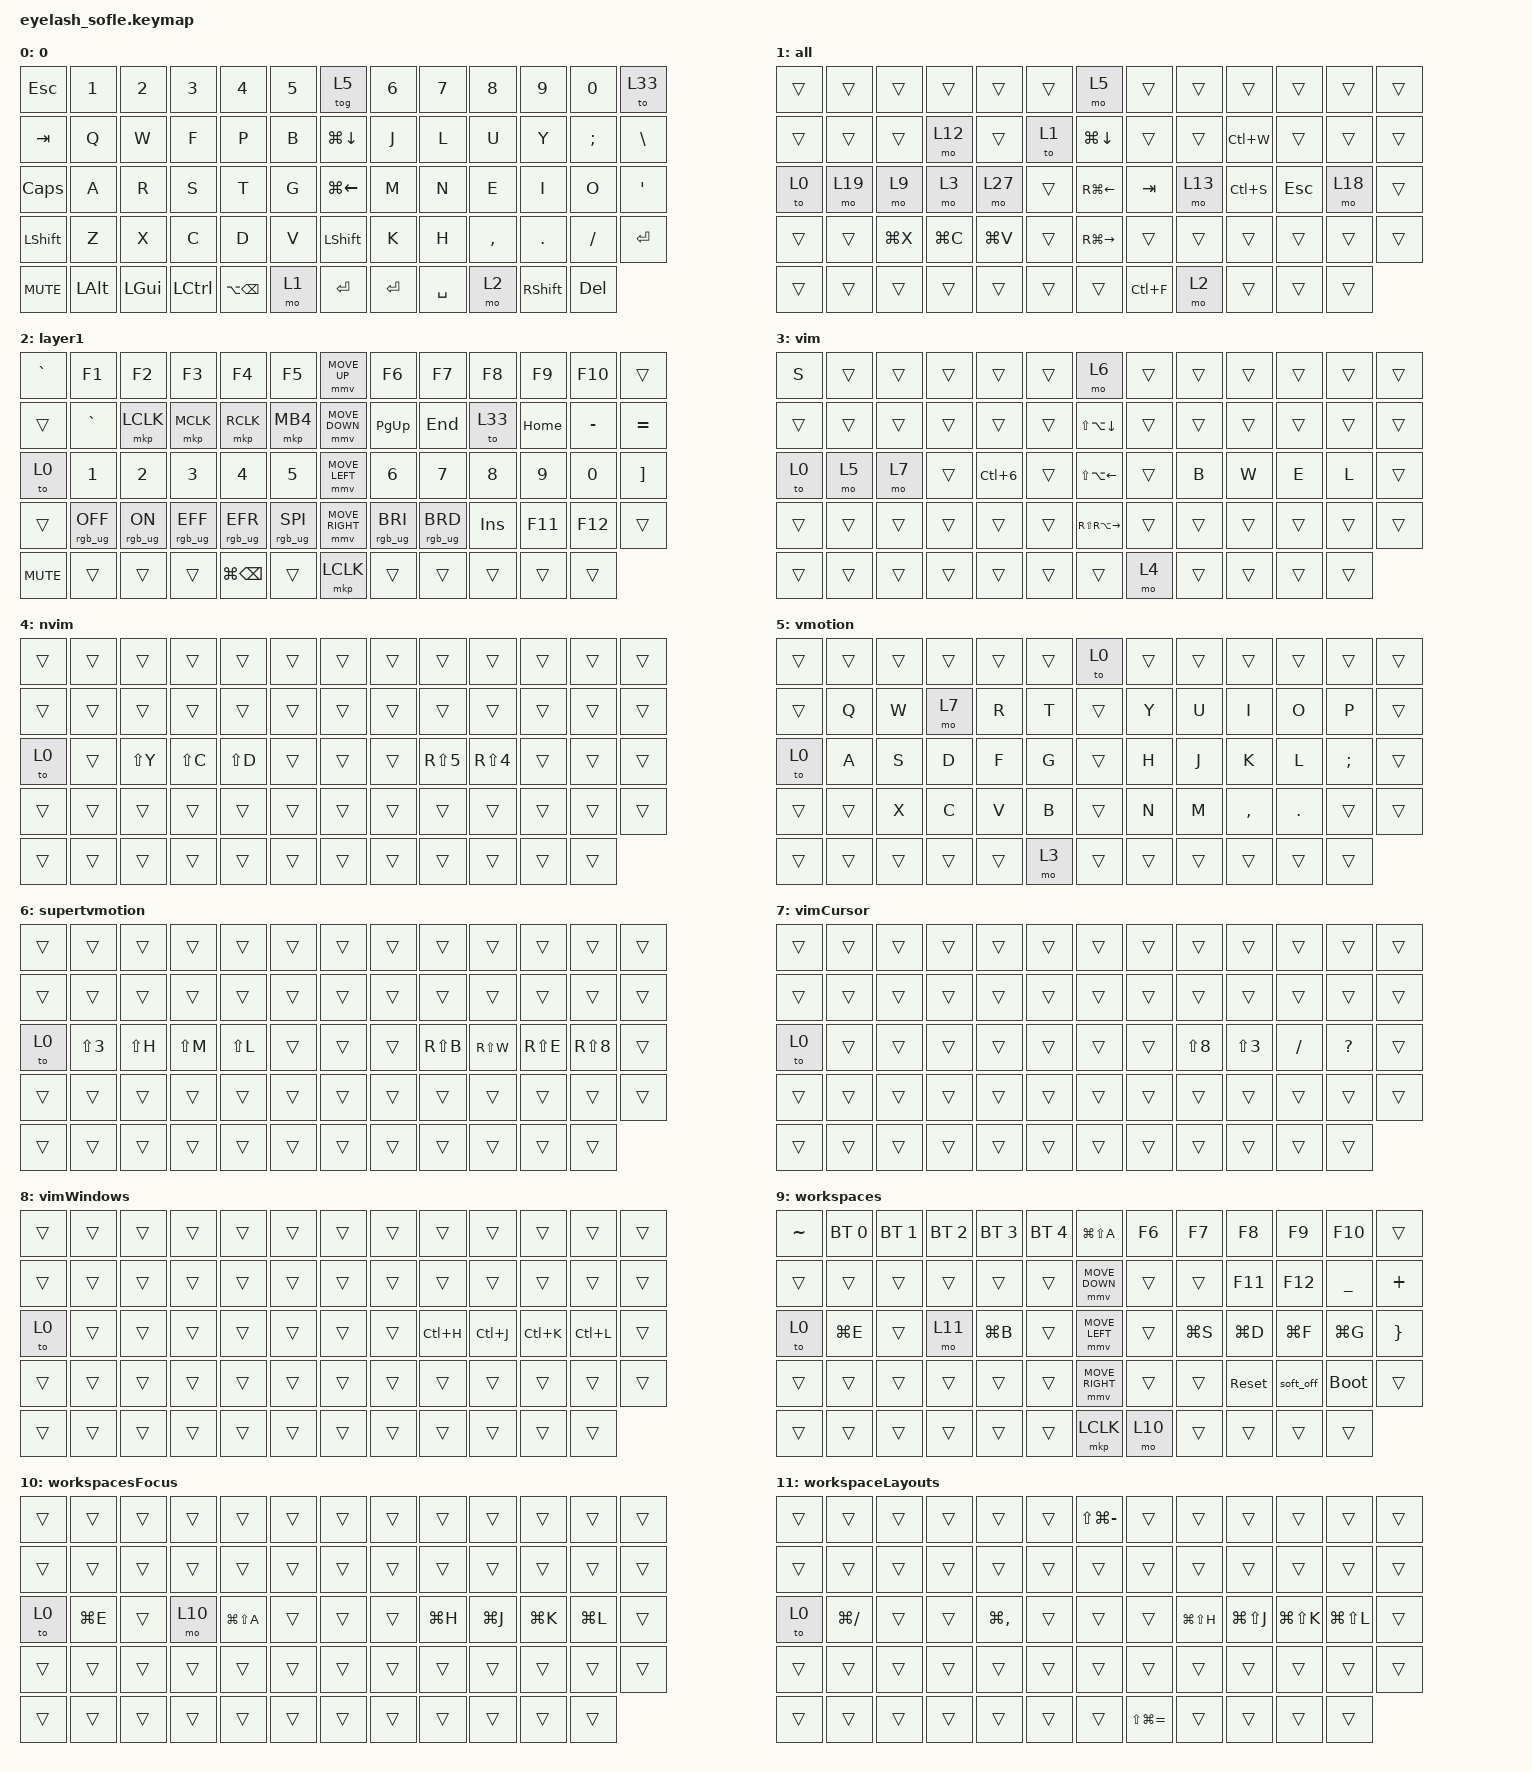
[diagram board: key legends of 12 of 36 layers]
#define ZMK_POINTING_DEFAULT_MOVE_VAL 1200  // 600
#define ZMK_POINTING_DEFAULT_SCRL_VAL 25   // 10

#include <input/processors.dtsi>
#include <zephyr/dt-bindings/input/input-event-codes.h>
#include <behaviors.dtsi>
#include <dt-bindings/zmk/bt.h>
#include <dt-bindings/zmk/keys.h>
#include <dt-bindings/zmk/pointing.h>
#include <dt-bindings/zmk/rgb.h>

&mmv_input_listener { input-processors = <&zip_xy_scaler 2 1>; };

&msc_input_listener { input-processors = <&zip_scroll_scaler 2 1>; };

&msc {
    acceleration-exponent = <1>;      // 0
    time-to-max-speed-ms = <100>;       // 300
    delay-ms = <0>;                   // 0
};

&mmv {
    time-to-max-speed-ms = <500>;
    acceleration-exponent = <1>;
    trigger-period-ms = <16>;
};

/ {
    scroll_encoder: scroll_encoder {
        compatible = "zmk,behavior-sensor-rotate";
        #sensor-binding-cells = <0>;
        bindings = <&msc SCRL_DOWN>, <&msc SCRL_UP>;

        tap-ms = <100>;
    };

    behaviors {
    };

    macros {
        password: new_macro {
            compatible = "zmk,behavior-macro";
            #binding-cells = <0>;
            bindings =
                <&none>,
                <&macro_press>,
                <&kp M &kp I &kp G &kp N1 &kp N9 &kp N9 &kp N6>;

            label = "NEW_MACRO";
        };
    };

    combos {
        compatible = "zmk,combos";

        ee {
            bindings = <&kp ESCAPE>;
            key-positions = <34 35>;
        };
    };

    keymap {
        compatible = "zmk,keymap";

        layer0 {
            bindings = <
&kp ESC     &kp N1        &kp N2        &kp N3            &kp N4             &kp N5    &tog 5              &kp N6   &kp N7     &kp N8     &kp N9           &kp N0         &to 33
&kp TAB     &kp Q         &kp W         &kp F             &kp P              &kp B     &kp LG(DOWN_ARROW)  &kp J    &kp L      &kp U      &kp Y            &kp SEMICOLON  &kp BSLH
&kp CAPS    &kp A         &kp R         &kp S             &kp T              &kp G     &kp LG(LEFT_ARROW)  &kp M    &kp N      &kp E      &kp I            &kp O          &kp APOS
&kp LSHFT   &kp Z         &kp X         &kp C             &kp D              &kp V     &kp LEFT_SHIFT      &kp K    &kp H      &kp COMMA  &kp DOT          &kp FSLH       &kp ENTER
&kp C_MUTE  &kp LEFT_ALT  &kp LEFT_GUI  &kp LEFT_CONTROL  &kp LA(BACKSPACE)  &mo 1     &kp ENTER           &kp RET  &kp SPACE  &mo 2      &kp RIGHT_SHIFT  &kp DELETE
            >;

            sensor-bindings = <&inc_dec_kp C_VOLUME_UP C_VOL_DN>;
            display-name = "0";
            label = "layer0";
        };

        all {
            bindings = <
&trans  &trans  &trans     &trans     &trans     &trans    &mo 5                &trans     &trans  &trans     &trans      &trans  &trans
&trans  &trans  &trans     &mo 12     &trans     &to 1     &kp LG(DOWN_ARROW)   &trans     &trans  &kp LC(W)  &trans      &trans  &trans
&to 0   &mo 19  &mo 9      &mo 3      &mo 27     &trans    &kp RG(LEFT_ARROW)   &kp TAB    &mo 13  &kp LC(S)  &kp ESCAPE  &mo 18  &trans
&trans  &trans  &kp LG(X)  &kp LG(C)  &kp LG(V)  &trans    &kp RG(RIGHT_ARROW)  &trans     &trans  &trans     &trans      &trans  &trans
&trans  &trans  &trans     &trans     &trans     &trans    &trans               &kp LC(F)  &mo 2   &trans     &trans      &trans
            >;
        };

        numbers {
            bindings = <
&kp GRAVE   &kp F1           &kp F2          &kp F3           &kp F4             &kp F5             &mmv MOVE_UP     &kp F6           &kp F7           &kp F8        &kp F9        &kp F10       &trans
&trans      &kp GRAVE        &mkp LCLK       &mkp MCLK        &mkp RCLK          &mkp MB4           &mmv MOVE_DOWN   &kp PG_UP        &kp END          &to 33        &kp HOME      &kp MINUS     &kp EQUAL
&to 0       &kp NUMBER_1     &kp NUMBER_2    &kp NUMBER_3     &kp NUMBER_4       &kp NUMBER_5       &mmv MOVE_LEFT   &kp NUMBER_6     &kp NUMBER_7     &kp NUMBER_8  &kp NUMBER_9  &kp NUMBER_0  &kp RIGHT_BRACKET
&trans      &rgb_ug RGB_OFF  &rgb_ug RGB_ON  &rgb_ug RGB_EFF  &rgb_ug RGB_EFR    &rgb_ug RGB_SPI    &mmv MOVE_RIGHT  &rgb_ug RGB_BRI  &rgb_ug RGB_BRD  &kp INSERT    &kp F11       &kp F12       &trans
&kp C_MUTE  &trans           &trans          &trans           &kp LG(BACKSPACE)  &trans             &mkp LCLK        &trans           &trans           &trans        &trans        &trans
            >;

            display-name = "layer1";
            sensor-bindings = <&scroll_encoder>;
        };

        vim {
            bindings = <
&kp S   &trans  &trans  &trans  &trans            &trans    &mo 6                    &trans  &trans  &trans  &trans  &trans  &trans
&trans  &trans  &trans  &trans  &trans            &trans    &kp LS(LA(DOWN_ARROW))   &trans  &trans  &trans  &trans  &trans  &trans
&to 0   &mo 5   &mo 7   &trans  &kp LC(NUMBER_6)  &trans    &kp LS(LA(LEFT_ARROW))   &trans  &kp B   &kp W   &kp E   &kp L   &trans
&trans  &trans  &trans  &trans  &trans            &trans    &kp RS(RA(RIGHT_ARROW))  &trans  &trans  &trans  &trans  &trans  &trans
&trans  &trans  &trans  &trans  &trans            &trans    &trans                   &mo 4   &trans  &trans  &trans  &trans
            >;
        };

        nvim {
            bindings = <
&trans  &trans  &trans     &trans     &trans     &trans    &trans  &trans  &trans      &trans            &trans  &trans  &trans
&trans  &trans  &trans     &trans     &trans     &trans    &trans  &trans  &trans      &trans            &trans  &trans  &trans
&to 0   &trans  &kp LS(Y)  &kp LS(C)  &kp LS(D)  &trans    &trans  &trans  &kp RS(N5)  &kp RS(NUMBER_4)  &trans  &trans  &trans
&trans  &trans  &trans     &trans     &trans     &trans    &trans  &trans  &trans      &trans            &trans  &trans  &trans
&trans  &trans  &trans     &trans     &trans     &trans    &trans  &trans  &trans      &trans            &trans  &trans
            >;
        };

        vmotion {
            bindings = <
&trans  &trans  &trans  &trans  &trans  &trans    &to 0   &trans  &trans  &trans     &trans      &trans    &trans
&trans  &kp Q   &kp W   &mo 7   &kp R   &kp T     &trans  &kp Y   &kp U   &kp I      &kp O       &kp P     &trans
&to 0   &kp A   &kp S   &kp D   &kp F   &kp G     &trans  &kp H   &kp J   &kp K      &kp L       &kp SEMI  &trans
&trans  &trans  &kp X   &kp C   &kp V   &kp B     &trans  &kp N   &kp M   &kp COMMA  &kp PERIOD  &trans    &trans
&trans  &trans  &trans  &trans  &trans  &mo 3     &trans  &trans  &trans  &trans     &trans      &trans
            >;
        };

        supertvmotion {
            bindings = <
&trans  &trans            &trans     &trans     &trans     &trans    &trans  &trans  &trans     &trans     &trans     &trans      &trans
&trans  &trans            &trans     &trans     &trans     &trans    &trans  &trans  &trans     &trans     &trans     &trans      &trans
&to 0   &kp LS(NUMBER_3)  &kp LS(H)  &kp LS(M)  &kp LS(L)  &trans    &trans  &trans  &kp RS(B)  &kp RS(W)  &kp RS(E)  &kp RS(N8)  &trans
&trans  &trans            &trans     &trans     &trans     &trans    &trans  &trans  &trans     &trans     &trans     &trans      &trans
&trans  &trans            &trans     &trans     &trans     &trans    &trans  &trans  &trans     &trans     &trans     &trans
            >;
        };

        vimCursor {
            bindings = <
&trans  &trans  &trans  &trans  &trans  &trans    &trans  &trans  &trans      &trans            &trans     &trans     &trans
&trans  &trans  &trans  &trans  &trans  &trans    &trans  &trans  &trans      &trans            &trans     &trans     &trans
&to 0   &trans  &trans  &trans  &trans  &trans    &trans  &trans  &kp LS(N8)  &kp LS(NUMBER_3)  &kp SLASH  &kp QMARK  &trans
&trans  &trans  &trans  &trans  &trans  &trans    &trans  &trans  &trans      &trans            &trans     &trans     &trans
&trans  &trans  &trans  &trans  &trans  &trans    &trans  &trans  &trans      &trans            &trans     &trans
            >;
        };

        vimWindows {
            bindings = <
&trans  &trans  &trans  &trans  &trans  &trans    &trans  &trans  &trans     &trans     &trans     &trans     &trans
&trans  &trans  &trans  &trans  &trans  &trans    &trans  &trans  &trans     &trans     &trans     &trans     &trans
&to 0   &trans  &trans  &trans  &trans  &trans    &trans  &trans  &kp LC(H)  &kp LC(J)  &kp LC(K)  &kp LC(L)  &trans
&trans  &trans  &trans  &trans  &trans  &trans    &trans  &trans  &trans     &trans     &trans     &trans     &trans
&trans  &trans  &trans  &trans  &trans  &trans    &trans  &trans  &trans     &trans     &trans     &trans
            >;
        };

        workspaces {
            bindings = <
&kp TILDE  &bt BT_SEL 0  &bt BT_SEL 1  &bt BT_SEL 2  &bt BT_SEL 3  &bt BT_SEL 4    &kp LG(LS(A))    &kp F6  &kp F7     &kp F8      &kp F9     &kp F10      &trans
&trans     &trans        &trans        &trans        &trans        &trans          &mmv MOVE_DOWN   &trans  &trans     &kp F11     &kp F12    &kp UNDER    &kp PLUS
&to 0      &kp LG(E)     &trans        &mo 11        &kp LG(B)     &trans          &mmv MOVE_LEFT   &trans  &kp LG(S)  &kp LG(D)   &kp LG(F)  &kp LG(G)    &kp RBRC
&trans     &trans        &trans        &trans        &trans        &trans          &mmv MOVE_RIGHT  &trans  &trans     &sys_reset  &soft_off  &bootloader  &trans
&trans     &trans        &trans        &trans        &trans        &trans          &mkp LCLK        &mo 10  &trans     &trans      &trans     &trans
            >;

            sensor-bindings = <&scroll_encoder>;
        };

        workspacesFocus {
            bindings = <
&trans  &trans     &trans  &trans  &trans         &trans    &trans  &trans  &trans     &trans     &trans     &trans     &trans
&trans  &trans     &trans  &trans  &trans         &trans    &trans  &trans  &trans     &trans     &trans     &trans     &trans
&to 0   &kp LG(E)  &trans  &mo 10  &kp LG(LS(A))  &trans    &trans  &trans  &kp LG(H)  &kp LG(J)  &kp LG(K)  &kp LG(L)  &trans
&trans  &trans     &trans  &trans  &trans         &trans    &trans  &trans  &trans     &trans     &trans     &trans     &trans
&trans  &trans     &trans  &trans  &trans         &trans    &trans  &trans  &trans     &trans     &trans     &trans
            >;
        };

        workspaceLayouts {
            bindings = <
&trans  &trans         &trans  &trans  &trans         &trans    &kp LS(LG(MINUS))  &trans             &trans         &trans         &trans         &trans         &trans
&trans  &trans         &trans  &trans  &trans         &trans    &trans             &trans             &trans         &trans         &trans         &trans         &trans
&to 0   &kp LG(SLASH)  &trans  &trans  &kp LG(COMMA)  &trans    &trans             &trans             &kp LG(LS(H))  &kp LG(LS(J))  &kp LG(LS(K))  &kp LG(LS(L))  &trans
&trans  &trans         &trans  &trans  &trans         &trans    &trans             &trans             &trans         &trans         &trans         &trans         &trans
&trans  &trans         &trans  &trans  &trans         &trans    &trans             &kp LS(LG(EQUAL))  &trans         &trans         &trans         &trans
            >;
        };

        shortcuts {
            bindings = <
&kp G   &trans     &trans  &trans         &trans  &trans    &trans  &trans         &trans   &trans       &trans         &trans  &trans
&trans  &trans     &trans  &trans         &trans  &trans    &trans  &trans         &trans   &trans       &trans         &trans  &trans
&to 0   &kp LG(M)  &kp W   &kp LC(LG(F))  &trans  &trans    &trans  &trans         &kp TAB  &kp LS(TAB)  &kp RIGHT_GUI  &trans  &trans
&trans  &trans     &trans  &trans         &trans  &trans    &trans  &trans         &trans   &trans       &trans         &trans  &trans
&trans  &trans     &trans  &trans         &trans  &trans    &trans  &kp RIGHT_GUI  &trans   &trans       &trans         &trans
            >;
        };

        browser {
            bindings = <
&trans  &trans             &trans                 &trans             &trans             &trans               &mo 16  &trans  &trans  &trans     &trans     &trans  &trans
&trans  &trans             &trans                 &kp LG(W)          &trans             &trans               &trans  &trans  &trans  &trans     &trans     &trans  &trans
&to 0   &kp LS(LC(LA(F)))  &kp LS(LA(LC(LG(Z))))  &kp LS(LA(LC(B)))  &kp LC(LA(LS(P)))  &kp LS(LA(LC(W)))    &trans  &trans  &trans  &kp LS(E)  &kp LS(R)  &mo 14  &trans
&trans  &trans             &trans                 &trans             &trans             &trans               &trans  &trans  &trans  &trans     &trans     &trans  &trans
&trans  &trans             &trans                 &trans             &trans             &trans               &trans  &mo 15  &trans  &trans     &trans     &trans
            >;
        };

        browserTabs {
            bindings = <
&trans  &trans  &trans  &trans     &trans     &trans    &trans  &trans  &trans     &trans     &trans     &trans  &trans
&trans  &trans  &trans  &trans     &trans     &trans    &trans  &trans  &trans     &trans     &trans     &trans  &trans
&to 0   &trans  &kp X   &kp LS(X)  &kp LG(T)  &trans    &trans  &trans  &kp LS(S)  &kp LS(D)  &kp LS(I)  &trans  &trans
&trans  &trans  &trans  &trans     &trans     &trans    &trans  &trans  &trans     &trans     &trans     &trans  &trans
&trans  &trans  &trans  &trans     &trans     &trans    &trans  &trans  &trans     &trans     &trans     &trans
            >;
        };

        browserShortcuts {
            bindings = <
&trans  &trans  &trans      &trans         &trans        &trans    &trans  &trans  &trans         &trans     &trans                 &trans                    &trans
&trans  &trans  &trans      &trans         &trans        &trans    &trans  &trans  &trans         &trans     &trans                 &trans                    &trans
&to 0   &trans  &kp LG(N0)  &kp LG(MINUS)  &kp LG(PLUS)  &trans    &trans  &trans  &kp LG(LS(P))  &kp LC(P)  &kp LS(LA(LC(LG(X))))  &kp LC(LA(LG(LS(SEMI))))  &trans
&trans  &trans  &trans      &trans         &trans        &trans    &trans  &trans  &trans         &trans     &trans                 &trans                    &trans
&trans  &trans  &trans      &trans         &trans        &trans    &trans  &trans  &trans         &trans     &trans                 &trans
            >;
        };

        browserBasics {
            bindings = <
&trans  &trans         &trans     &trans  &trans     &trans    &trans  &trans  &trans     &trans         &trans         &trans         &trans
&trans  &trans         &trans     &trans  &trans     &trans    &trans  &trans  &trans     &trans         &trans         &trans         &trans
&to 0   &kp LC(LS(Q))  &kp LG(U)  &trans  &kp LG(M)  &trans    &trans  &trans  &kp LG(Y)  &kp LG(LC(B))  &kp LG(EQUAL)  &kp LC(SLASH)  &trans
&trans  &trans         &trans     &trans  &trans     &trans    &trans  &trans  &trans     &trans         &trans         &trans         &trans
&trans  &trans         &trans     &trans  &trans     &trans    &trans  &trans  &trans     &trans         &trans         &trans
            >;
        };

        surfingkey {
            bindings = <
&trans  &trans  &trans  &trans  &trans  &trans    &trans  &trans     &trans  &trans  &trans  &trans  &trans
&trans  &trans  &trans  &trans  &trans  &trans    &trans  &trans     &trans  &trans  &trans  &trans  &trans
&to 0   &trans  &trans  &trans  &trans  &trans    &trans  &trans     &trans  &trans  &trans  &trans  &trans
&trans  &trans  &trans  &trans  &trans  &trans    &trans  &trans     &trans  &trans  &trans  &trans  &trans
&trans  &trans  &trans  &trans  &trans  &trans    &trans  &kp SLASH  &trans  &trans  &trans  &trans
            >;
        };

        coding {
            bindings = <
&trans  &trans      &trans      &trans          &trans           &trans    &trans  &trans  &trans   &trans            &trans             &trans  &trans
&trans  &trans      &trans      &trans          &trans           &trans    &trans  &trans  &trans   &trans            &trans             &trans  &trans
&to 0   &kp LS(N9)  &kp LS(N0)  &kp LEFT_BRACE  &kp RIGHT_BRACE  &trans    &trans  &trans  &kp TAB  &kp LEFT_BRACKET  &kp RIGHT_BRACKET  &trans  &trans
&trans  &trans      &trans      &trans          &trans           &trans    &trans  &trans  &trans   &trans            &trans             &trans  &trans
&trans  &trans      &trans      &trans          &trans           &trans    &trans  &trans  &trans   &trans            &trans             &trans
            >;
        };

        arrowMovements {
            bindings = <
&trans  &trans  &trans  &trans  &trans  &trans    &mo 24  &trans  &trans          &trans                &trans          &trans           &trans
&trans  &trans  &trans  &trans  &trans  &trans    &trans  &trans  &trans          &kp LS(LA(UP_ARROW))  &trans          &trans           &trans
&to 0   &trans  &mo 20  &mo 21  &mo 20  &trans    &trans  &trans  &kp DOWN_ARROW  &kp UP_ARROW          &kp LEFT_ARROW  &kp RIGHT_ARROW  &trans
&trans  &trans  &trans  &trans  &trans  &trans    &trans  &trans  &trans          &trans                &trans          &trans           &trans
&trans  &trans  &trans  &trans  &trans  &trans    &trans  &mo 23  &trans          &trans                &trans          &trans
            >;
        };

        AltarrowsMovements {
            bindings = <
&trans  &trans  &trans  &trans  &trans  &trans    &trans  &trans  &trans              &trans            &trans              &trans               &trans
&trans  &trans  &trans  &trans  &trans  &trans    &trans  &trans  &trans              &trans            &trans              &trans               &trans
&to 0   &trans  &trans  &trans  &trans  &trans    &trans  &trans  &kp RA(DOWN_ARROW)  &kp RA(UP_ARROW)  &kp RA(LEFT_ARROW)  &kp RA(RIGHT_ARROW)  &trans
&trans  &trans  &trans  &trans  &trans  &trans    &trans  &trans  &trans              &trans            &trans              &trans               &trans
&trans  &trans  &trans  &trans  &trans  &trans    &trans  &trans  &trans              &trans            &trans              &trans
            >;
        };

        GuiarrowsMovements {
            bindings = <
&trans  &trans  &trans  &trans  &trans  &trans    &trans  &trans  &trans              &trans            &trans              &trans               &trans
&trans  &trans  &trans  &trans  &trans  &trans    &trans  &trans  &trans              &trans            &trans              &trans               &trans
&to 0   &trans  &trans  &trans  &trans  &trans    &trans  &trans  &kp RG(DOWN_ARROW)  &kp RG(UP_ARROW)  &kp RG(LEFT_ARROW)  &kp RG(RIGHT_ARROW)  &trans
&trans  &trans  &trans  &trans  &trans  &trans    &trans  &trans  &trans              &trans            &trans              &trans               &trans
&trans  &trans  &trans  &trans  &trans  &trans    &trans  &trans  &trans              &trans            &trans              &trans
            >;
        };

        AltShiftarrowsMovements {
            bindings = <
&trans  &trans  &trans  &trans  &trans  &trans    &trans  &trans  &trans                  &trans                &trans                  &trans                   &trans
&trans  &trans  &trans  &trans  &trans  &trans    &trans  &trans  &trans                  &trans                &trans                  &trans                   &trans
&to 0   &trans  &trans  &trans  &trans  &trans    &trans  &trans  &kp LS(LA(DOWN_ARROW))  &kp LS(LA(UP_ARROW))  &kp LS(LA(LEFT_ARROW))  &kp LS(LA(RIGHT_ARROW))  &trans
&trans  &trans  &trans  &trans  &trans  &trans    &trans  &trans  &trans                  &trans                &trans                  &trans                   &trans
&trans  &trans  &trans  &trans  &trans  &trans    &trans  &trans  &trans                  &trans                &trans                  &trans
            >;
        };

        shellMovements {
            bindings = <
&trans  &trans  &trans  &trans  &trans  &trans    &trans  &trans  &trans     &trans     &trans     &trans     &trans
&trans  &trans  &trans  &trans  &trans  &trans    &trans  &trans  &trans     &trans     &trans     &trans     &trans
&to 0   &trans  &mo 26  &mo 25  &mo 24  &trans    &trans  &trans  &kp RC(A)  &kp RC(E)  &kp RA(B)  &kp RA(F)  &trans
&trans  &trans  &trans  &trans  &trans  &trans    &trans  &trans  &trans     &trans     &trans     &trans     &trans
&trans  &trans  &trans  &trans  &trans  &trans    &trans  &trans  &trans     &trans     &trans     &trans
            >;
        };

        shellActions {
            bindings = <
&trans  &trans  &trans          &trans   &trans  &trans    &trans  &trans  &trans     &trans     &trans     &trans         &trans
&trans  &trans  &trans          &trans   &trans  &trans    &trans  &trans  &trans     &trans     &trans     &trans         &trans
&to 0   &trans  &kp LA(PERIOD)  &kp TAB  &trans  &trans    &trans  &trans  &kp RC(Y)  &kp RA(T)  &kp RC(T)  &kp RC(UNDER)  &trans
&trans  &trans  &trans          &trans   &trans  &trans    &trans  &trans  &trans     &trans     &trans     &trans         &trans
&trans  &trans  &trans          &trans   &trans  &trans    &trans  &trans  &trans     &trans     &trans     &trans
            >;
        };

        shellDeletion {
            bindings = <
&trans  &trans  &trans  &trans  &trans              &trans    &trans  &trans  &trans     &trans     &trans     &trans     &trans
&trans  &trans  &trans  &trans  &trans              &trans    &trans  &trans  &trans     &trans     &trans     &trans     &trans
&to 0   &trans  &trans  &trans  &kp LS(LA(PERIOD))  &trans    &trans  &trans  &kp RC(W)  &kp RA(D)  &kp RC(U)  &kp RC(K)  &trans
&trans  &trans  &trans  &trans  &trans              &trans    &trans  &trans  &trans     &trans     &trans     &trans     &trans
&trans  &trans  &trans  &trans  &trans              &trans    &trans  &trans  &trans     &trans     &trans     &trans
            >;
        };

        shellHistory {
            bindings = <
&trans  &trans  &trans  &trans  &trans  &trans    &trans  &trans  &trans     &trans     &trans     &trans     &trans
&trans  &trans  &trans  &trans  &trans  &trans    &trans  &trans  &trans     &trans     &trans     &trans     &trans
&to 0   &trans  &trans  &trans  &trans  &trans    &trans  &trans  &kp RC(C)  &kp RC(R)  &kp RC(G)  &kp RC(L)  &trans
&trans  &trans  &trans  &trans  &trans  &trans    &trans  &trans  &trans     &trans     &trans     &trans     &trans
&trans  &trans  &trans  &trans  &trans  &trans    &trans  &trans  &trans     &trans     &trans     &trans
            >;
        };

        raycast {
            bindings = <
&trans  &trans              &trans  &trans             &trans         &trans    &trans  &trans                 &trans             &trans                  &trans                 &trans                 &trans
&trans  &trans              &trans  &kp LS(LA(LC(G)))  &kp LS(LC(Q))  &trans    &trans  &trans                 &trans             &kp LS(LA(LG(PERIOD)))  &trans                 &trans                 &trans
&to 0   &kp LS(LG(PERIOD))  &mo 28  &mo 31             &trans         &trans    &trans  &kp LS(LG(LC(LA(Y))))  &kp LS(LC(COMMA))  &kp LS(LA(LC(LG(U))))   &kp LC(LA(LS(LG(I))))  &kp LC(LA(LS(X)))      &trans
&trans  &trans              &trans  &trans             &trans         &trans    &trans  &trans                 &trans             &trans                  &trans                 &kp LS(LC(LA(SLASH)))  &trans
&trans  &trans              &trans  &trans             &trans         &trans    &trans  &kp LC(LA(Y))          &kp RG(COMMA)      &trans                  &trans                 &trans
            >;
        };

        raycastApps {
            bindings = <
&trans  &trans  &trans  &trans  &trans  &trans    &trans  &trans         &trans             &trans                 &trans                 &trans                 &trans
&trans  &trans  &trans  &trans  &trans  &trans    &trans  &trans         &trans             &kp LS(LG(LA(LC(D))))  &trans                 &trans                 &trans
&to 0   &trans  &trans  &mo 29  &trans  &trans    &trans  &kp LS(LG(Z))  &kp LA(LS(LG(G)))  &kp LG(K)              &kp LA(LS(LC(LG(L))))  &kp LS(LA(LC(LG(K))))  &trans
&trans  &trans  &trans  &trans  &trans  &trans    &trans  &trans         &trans             &trans                 &trans                 &trans                 &trans
&trans  &trans  &trans  &trans  &trans  &trans    &trans  &kp LC(LS(Q))  &trans             &trans                 &trans                 &trans
            >;
        };

        raycastAppsTwo {
            bindings = <
&trans  &trans  &trans  &trans  &trans  &trans    &trans  &trans                 &trans                 &trans                 &trans                 &trans  &trans
&trans  &trans  &trans  &trans  &trans  &trans    &trans  &trans                 &trans                 &kp LS(LG(LA(LC(H))))  &trans                 &trans  &trans
&to 0   &trans  &trans  &trans  &trans  &trans    &trans  &trans                 &kp LS(LA(LC(LG(O))))  &kp LG(LS(Z))          &kp LS(LA(LC(LG(W))))  &mo 30  &trans
&trans  &trans  &trans  &trans  &trans  &trans    &trans  &trans                 &trans                 &trans                 &trans                 &trans  &trans
&trans  &trans  &trans  &trans  &trans  &trans    &trans  &kp LC(LG(LA(LS(B))))  &kp LG(LA(LS(LC(M))))  &trans                 &trans                 &trans
            >;
        };

        raycastAppsThree {
            bindings = <
&trans  &trans  &trans  &trans  &trans  &trans    &trans  &trans             &trans         &trans                 &trans                 &trans  &trans
&trans  &trans  &trans  &trans  &trans  &trans    &trans  &trans             &trans         &trans                 &trans                 &trans  &trans
&to 0   &trans  &trans  &trans  &trans  &trans    &trans  &trans             &kp LA(LC(Y))  &kp LS(LA(LC(LG(A))))  &kp LS(LA(LG(LC(P))))  &trans  &trans
&trans  &trans  &trans  &trans  &trans  &trans    &trans  &trans             &trans         &trans                 &trans                 &trans  &trans
&trans  &trans  &trans  &trans  &trans  &trans    &trans  &kp LS(LG(LA(B)))  &trans         &trans                 &trans                 &trans
            >;
        };

        tmuxGhostty {
            bindings = <
&trans  &trans  &trans  &trans  &trans  &trans    &trans  &trans  &trans         &trans             &trans                 &trans                         &trans
&trans  &trans  &trans  &trans  &trans  &trans    &trans  &trans  &trans         &trans             &trans                 &trans                         &trans
&to 0   &trans  &trans  &trans  &trans  &trans    &trans  &trans  &kp LC(LS(R))  &kp LS(LA(LC(N)))  &kp LA(LS(LC(LG(Z))))  &kp LS(LA(LG(LC(SEMICOLON))))  &trans
&trans  &trans  &trans  &trans  &trans  &trans    &trans  &trans  &trans         &trans             &trans                 &trans                         &trans
&trans  &trans  &trans  &trans  &trans  &trans    &trans  &trans  &trans         &trans             &trans                 &trans
            >;
        };

        GUIkey {
            bindings = <
&trans  &trans     &trans     &trans     &trans     &trans       &trans  &trans     &trans     &trans         &trans          &trans             &trans
&trans  &kp LG(Q)  &kp LG(W)  &kp LG(F)  &kp LG(P)  &kp LG(B)    &trans  &kp RG(J)  &kp RG(L)  &kp RG(U)      &kp RG(Y)       &kp RG(SEMICOLON)  &trans
&to 0   &kp LG(A)  &kp LG(R)  &kp LG(S)  &kp LG(T)  &kp LG(G)    &trans  &kp RG(M)  &kp RG(N)  &kp RG(E)      &kp RG(I)       &kp RG(O)          &trans
&trans  &kp LG(Z)  &kp LG(X)  &kp LG(C)  &kp LG(D)  &kp LG(V)    &trans  &kp RG(K)  &kp RG(H)  &kp RG(COMMA)  &kp RG(PERIOD)  &kp RG(SLASH)      &trans
&trans  &trans     &trans     &trans     &trans     &trans       &trans  &trans     &trans     &trans         &trans          &trans
            >;
        };

        figma {
            bindings = <
&trans  &kp NUMBER_1  &kp NUMBER_2  &kp NUMBER_3    &kp NUMBER_4      &kp N5           &trans  &kp NUMBER_6  &kp N7  &kp N8  &kp N9  &kp N0  &trans
&trans  &trans        &kp LG(C)     &kp LG(V)       &trans            &trans           &trans  &trans        &trans  &trans  &trans  &trans  &trans
&to 0   &kp DEL       &kp LG(Z)     &kp LEFT_SHIFT  &kp LEFT_CONTROL  &kp LA(LG(K))    &trans  &trans        &none   &trans  &trans  &trans  &trans
&trans  &trans        &trans        &kp LA(LS(S))   &kp LG(D)         &kp LS(LG(K))    &trans  &trans        &trans  &trans  &trans  &trans  &trans
&trans  &trans        &trans        &to 0           &mo 35            &mo 34           &trans  &trans        &trans  &trans  &trans  &trans
            >;
        };

        figmaNumbers {
            bindings = <
&trans  &trans        &trans  &trans  &trans  &trans    &trans  &trans  &trans  &trans  &trans  &trans  &trans
&trans  &trans        &trans  &kp N0  &trans  &trans    &trans  &trans  &trans  &trans  &trans  &trans  &trans
&to 0   &kp NUMBER_6  &kp N7  &kp N8  &kp N9  &trans    &trans  &trans  &trans  &trans  &trans  &trans  &trans
&trans  &trans        &trans  &trans  &trans  &trans    &trans  &trans  &trans  &trans  &trans  &trans  &trans
&trans  &trans        &trans  &trans  &trans  &trans    &trans  &trans  &trans  &trans  &trans  &trans
            >;
        };

       figmaNumbersTwo {
    bindings = <
&trans        &trans        &trans        &trans        &trans    &trans
&trans    &trans        &trans        &kp N5        &trans        &trans    &trans
&tog 0    &kp NUMBER_1  &kp NUMBER_2  &kp NUMBER_3  &kp NUMBER_4  &trans    &trans
&trans    &trans        &trans        &trans        &trans        &trans    &trans
&trans    &trans        &trans        &trans        &trans        &trans    &trans
            >;
};
    };
};
